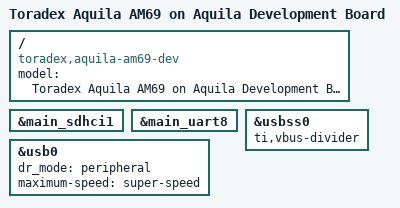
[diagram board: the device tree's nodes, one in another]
// SPDX-License-Identifier: GPL-2.0-or-later OR MIT
/*
 * Copyright 2024 Toradex
 *
 * Device tree for Toradex Aquila AM69 SoM on Aquila development carrier board
 *
 * https://www.toradex.com/computer-on-modules/aquila-arm-family/ti-am69
 * https://www.toradex.com/products/carrier-board/aquila-development-board-kit
 */

/dts-v1/;

#include "k3-j784s4.dtsi"
#include "k3-am69-aquila.dtsi"

/ {
	model = "Toradex Aquila AM69 on Aquila Development Board";
	compatible = "toradex,aquila-am69-dev",
		     "toradex,aquila-am69",
		     "ti,j784s4";
};

/* Aquila SD_1 */
&main_sdhci1 {
	status = "okay";
};

/* Aquila UART_3, used as the Linux console */
&main_uart8 {
	status = "okay";
};

&usb0 {
	dr_mode = "peripheral";
	maximum-speed = "super-speed";
};

&usbss0 {
	status = "okay";
	ti,vbus-divider;
};
